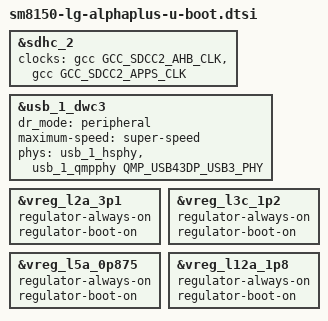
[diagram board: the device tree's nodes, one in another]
// SPDX-License-Identifier: BSD-3-Clause
/*
 * U-Boot additions for LG LM-G820N (Qualcomm SM8150)
 *
 * Copyright (c) 2026 AlphaPlus Porting Project
 */

#include <dt-bindings/phy/phy-qcom-qmp.h>

&sdhc_2 {
	clocks = <&gcc GCC_SDCC2_AHB_CLK>,
		 <&gcc GCC_SDCC2_APPS_CLK>;
	clock-names = "iface", "core";
};

&usb_1_dwc3 {
	dr_mode = "peripheral";
	maximum-speed = "super-speed";
	phys = <&usb_1_hsphy>,
	       <&usb_1_qmpphy QMP_USB43DP_USB3_PHY>;
	phy-names = "usb2-phy", "usb3-phy";
};

&vreg_l2a_3p1 {
	regulator-always-on;
	regulator-boot-on;
};

&vreg_l3c_1p2 {
	regulator-always-on;
	regulator-boot-on;
};

&vreg_l5a_0p875 {
	regulator-always-on;
	regulator-boot-on;
};

&vreg_l12a_1p8 {
	regulator-always-on;
	regulator-boot-on;
};
